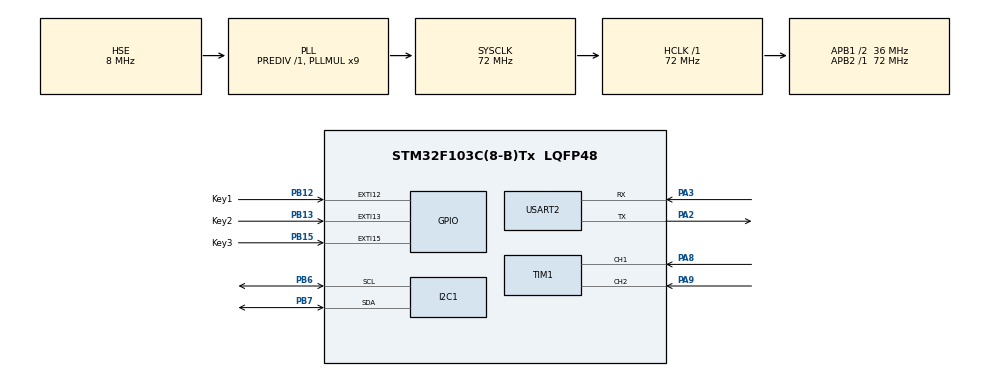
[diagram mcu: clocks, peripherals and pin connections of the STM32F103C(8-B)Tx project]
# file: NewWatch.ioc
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Dma.I2C1_TX.0.Direction=DMA_MEMORY_TO_PERIPH
Dma.I2C1_TX.0.Instance=DMA1_Channel6
Dma.I2C1_TX.0.MemDataAlignment=DMA_MDATAALIGN_BYTE
Dma.I2C1_TX.0.MemInc=DMA_MINC_ENABLE
Dma.I2C1_TX.0.Mode=DMA_NORMAL
Dma.I2C1_TX.0.PeriphDataAlignment=DMA_PDATAALIGN_BYTE
Dma.I2C1_TX.0.PeriphInc=DMA_PINC_DISABLE
Dma.I2C1_TX.0.Priority=DMA_PRIORITY_LOW
Dma.Request0=I2C1_TX
FREERTOS.BinarySemaphores01=KeySem1,Dynamic,NULL,Depleted;oled_dma_sem,Dynamic,NULL,Available
FREERTOS.Queues01=KeyTransmitQueue,16,key_type,0,Dynamic,NULL,NULL;EncoderHandle,16,Knob_message,0,Dynamic,NULL,NULL
FREERTOS.Tasks01=KeyForwardTask,8,128,StartForward,As weak,NULL,Dynamic,NULL,NULL;DisplayTask1,24,256,StartDisplay1,As external,NULL,Dynamic,NULL,NULL;RtcTask,8,128,StartRTC,As external,NULL,Dynamic,NULL,NULL;EncoderTask,40,128,StartEncoder,As external,NULL,Dynamic,NULL,NULL
FREERTOS.configTOTAL_HEAP_SIZE=6042
I2C1.I2C_Mode=I2C_Fast
Mcu.Family=STM32F1
Mcu.Name=STM32F103C(8-B)Tx
Mcu.Package=LQFP48
NVIC.DMA1_Channel6_IRQn=true\:5\:0\:false\:false\:true\:true\:false\:true\:true
NVIC.EXTI15_10_IRQn=true\:7\:0\:true\:false\:true\:false\:true\:true\:true
NVIC.I2C1_EV_IRQn=true\:5\:0\:false\:false\:true\:true\:true\:true\:true
NVIC.PriorityGroup=NVIC_PRIORITYGROUP_4
NVIC.TIM4_IRQn=true\:15\:0\:false\:false\:true\:false\:false\:true\:true
NVIC.TimeBase=TIM4_IRQn
NVIC.TimeBaseIP=TIM4
PA13.Mode=Serial_Wire
PA13.Signal=SYS_JTMS-SWDIO
PA14.Mode=Serial_Wire
PA14.Signal=SYS_JTCK-SWCLK
PA2.Mode=Asynchronous
PA2.Signal=USART2_TX
PA3.Mode=Asynchronous
PA3.Signal=USART2_RX
PA8.Signal=S_TIM1_CH1
PA9.Signal=S_TIM1_CH2
PB12.GPIO_Label=Key1
PB12.GPIO_ModeDefaultEXTI=GPIO_MODE_IT_FALLING
PB12.Signal=GPXTI12
PB13.GPIO_Label=Key2
PB13.GPIO_ModeDefaultEXTI=GPIO_MODE_IT_FALLING
PB13.GPIO_PuPd=GPIO_PULLUP
PB13.Signal=GPXTI13
PB15.GPIO_Label=Key3
PB15.GPIO_ModeDefaultEXTI=GPIO_MODE_IT_FALLING
PB15.GPIO_PuPd=GPIO_PULLUP
PB15.Signal=GPXTI15
PB6.Mode=I2C
PB6.Signal=I2C1_SCL
PB7.Mode=I2C
PB7.Signal=I2C1_SDA
PC14-OSC32_IN.Mode=LSE-External-Oscillator
PC14-OSC32_IN.Signal=RCC_OSC32_IN
PC15-OSC32_OUT.Mode=LSE-External-Oscillator
PC15-OSC32_OUT.Signal=RCC_OSC32_OUT
PD0-OSC_IN.Mode=HSE-External-Oscillator
PD0-OSC_IN.Signal=RCC_OSC_IN
PD1-OSC_OUT.Mode=HSE-External-Oscillator
PD1-OSC_OUT.Signal=RCC_OSC_OUT
ProjectManager.HeapSize=0x200
ProjectManager.StackSize=0x400
ProjectManager.TargetToolchain=CMake
RCC.AHBFreq_Value=72000000
RCC.APB1CLKDivider=RCC_HCLK_DIV2
RCC.APB1Freq_Value=36000000
RCC.APB1TimFreq_Value=72000000
RCC.APB2Freq_Value=72000000
RCC.APB2TimFreq_Value=72000000
RCC.HCLKFreq_Value=72000000
RCC.PLLMUL=RCC_PLL_MUL9
RCC.PLLSourceVirtual=RCC_PLLSOURCE_HSE
RCC.RTCClockSelection=RCC_RTCCLKSOURCE_LSE
RCC.SYSCLKFreq_VALUE=72000000
RCC.SYSCLKSource=RCC_SYSCLKSOURCE_PLLCLK
RCC.USBFreq_Value=72000000
SH.S_TIM1_CH1.0=TIM1_CH1,Encoder_Interface
SH.S_TIM1_CH2.0=TIM1_CH2,Encoder_Interface
TIM1.IC2Polarity=TIM_ICPOLARITY_FALLING
USART2.VirtualMode=VM_ASYNC
VP_FREERTOS_VS_CMSIS_V2.Mode=CMSIS_V2
VP_RTC_VS_RTC_Activate.Mode=RTC_Enabled
VP_SYS_VS_tim4.Mode=TIM4
board=custom

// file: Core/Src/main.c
/* USER CODE BEGIN Header */
/**
  ******************************************************************************
  * @file           : main.c
  * @brief          : Main program body
  ******************************************************************************
  * @attention
  *
  * Copyright (c) 2026 STMicroelectronics.
  * All rights reserved.
  *
  * This software is licensed under terms that can be found in the LICENSE file
  * in the root directory of this software component.
  * If no LICENSE file comes with this software, it is provided AS-IS.
  *
  ******************************************************************************
  */
/* USER CODE END Header */
#include "main.h"
#include "cmsis_os.h"
#include "dma.h"
#include "i2c.h"
#include "rtc.h"
#include "tim.h"
#include "usart.h"
#include "gpio.h"

void SystemClock_Config(void);
void MX_FREERTOS_Init(void);

int main(void)
{

  /* MCU Configuration--------------------------------------------------------*/

  /* Reset of all peripherals, Initializes the Flash interface and the Systick. */
  HAL_Init();

  /* Configure the system clock */
  SystemClock_Config();

  /* Initialize all configured peripherals */
  MX_GPIO_Init();
  MX_DMA_Init();
  MX_I2C1_Init();
  MX_USART2_UART_Init();
  MX_RTC_Init();
  MX_TIM1_Init();

  /* Init scheduler */
  osKernelInitialize();  /* Call init function for freertos objects (in cmsis_os2.c) */
  MX_FREERTOS_Init();

  /* Start scheduler */
  osKernelStart();

  /* We should never get here as control is now taken by the scheduler */

  /* Infinite loop */
  while (1)
  {

  }
}

void SystemClock_Config(void)
{
  RCC_OscInitTypeDef RCC_OscInitStruct = {0};
  RCC_ClkInitTypeDef RCC_ClkInitStruct = {0};
  RCC_PeriphCLKInitTypeDef PeriphClkInit = {0};

  /** Initializes the RCC Oscillators according to the specified parameters
  * in the RCC_OscInitTypeDef structure.
  */
  RCC_OscInitStruct.OscillatorType = RCC_OSCILLATORTYPE_HSE|RCC_OSCILLATORTYPE_LSE;
  RCC_OscInitStruct.HSEState = RCC_HSE_ON;
  RCC_OscInitStruct.HSEPredivValue = RCC_HSE_PREDIV_DIV1;
  RCC_OscInitStruct.LSEState = RCC_LSE_ON;
  RCC_OscInitStruct.HSIState = RCC_HSI_ON;
  RCC_OscInitStruct.PLL.PLLState = RCC_PLL_ON;
  RCC_OscInitStruct.PLL.PLLSource = RCC_PLLSOURCE_HSE;
  RCC_OscInitStruct.PLL.PLLMUL = RCC_PLL_MUL9;
  if (HAL_RCC_OscConfig(&RCC_OscInitStruct) != HAL_OK)
  {
    Error_Handler();
  }

  /** Initializes the CPU, AHB and APB buses clocks
  */
  RCC_ClkInitStruct.ClockType = RCC_CLOCKTYPE_HCLK|RCC_CLOCKTYPE_SYSCLK
                              |RCC_CLOCKTYPE_PCLK1|RCC_CLOCKTYPE_PCLK2;
  RCC_ClkInitStruct.SYSCLKSource = RCC_SYSCLKSOURCE_PLLCLK;
  RCC_ClkInitStruct.AHBCLKDivider = RCC_SYSCLK_DIV1;
  RCC_ClkInitStruct.APB1CLKDivider = RCC_HCLK_DIV2;
  RCC_ClkInitStruct.APB2CLKDivider = RCC_HCLK_DIV1;

  if (HAL_RCC_ClockConfig(&RCC_ClkInitStruct, FLASH_LATENCY_2) != HAL_OK)
  {
    Error_Handler();
  }
  PeriphClkInit.PeriphClockSelection = RCC_PERIPHCLK_RTC;
  PeriphClkInit.RTCClockSelection = RCC_RTCCLKSOURCE_LSE;
  if (HAL_RCCEx_PeriphCLKConfig(&PeriphClkInit) != HAL_OK)
  {
    Error_Handler();
  }
}

void HAL_TIM_PeriodElapsedCallback(TIM_HandleTypeDef *htim)
{
  if (htim->Instance == TIM4)
  {
    HAL_IncTick();
  }
}

void Error_Handler(void)
{
  __disable_irq();
  while (1)
  {
  }
}

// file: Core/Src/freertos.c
/* USER CODE BEGIN Header */
/**
  ******************************************************************************
  * File Name          : freertos.c
  * Description        : Code for freertos applications
  ******************************************************************************
  * @attention
  *
  * Copyright (c) 2026 STMicroelectronics.
  * All rights reserved.
  *
  * This software is licensed under terms that can be found in the LICENSE file
  * in the root directory of this software component.
  * If no LICENSE file comes with this software, it is provided AS-IS.
  *
  ******************************************************************************
  */
/* USER CODE END Header */

#include "FreeRTOS.h"
#include "task.h"
#include "main.h"
#include "cmsis_os.h"

/* USER CODE BEGIN Includes */
#include "keycontrol.h"
#include "knob.h"
#include <string.h>
/* USER CODE END Includes */

/* Definitions for KeyForwardTask */
osThreadId_t KeyForwardTaskHandle;
const osThreadAttr_t KeyForwardTask_attributes = {
  .name = "KeyForwardTask",
  .stack_size = 128 * 4,
  .priority = (osPriority_t) osPriorityLow,
};
/* Definitions for DisplayTask1 */
osThreadId_t DisplayTask1Handle;
const osThreadAttr_t DisplayTask1_attributes = {
  .name = "DisplayTask1",
  .stack_size = 256 * 4,
  .priority = (osPriority_t) osPriorityNormal,
};
/* Definitions for RtcTask */
osThreadId_t RtcTaskHandle;
const osThreadAttr_t RtcTask_attributes = {
  .name = "RtcTask",
  .stack_size = 128 * 4,
  .priority = (osPriority_t) osPriorityLow,
};
/* Definitions for EncoderTask */
osThreadId_t EncoderTaskHandle;
const osThreadAttr_t EncoderTask_attributes = {
  .name = "EncoderTask",
  .stack_size = 128 * 4,
  .priority = (osPriority_t) osPriorityHigh,
};
/* Definitions for KeyTransmitQueue */
osMessageQueueId_t KeyTransmitQueueHandle;
const osMessageQueueAttr_t KeyTransmitQueue_attributes = {
  .name = "KeyTransmitQueue"
};
/* Definitions for EncoderHandle */
osMessageQueueId_t EncoderHandleHandle;
const osMessageQueueAttr_t EncoderHandle_attributes = {
  .name = "EncoderHandle"
};
/* Definitions for KeySem1 */
osSemaphoreId_t KeySem1Handle;
const osSemaphoreAttr_t KeySem1_attributes = {
  .name = "KeySem1"
};
/* Definitions for oled_dma_sem */
osSemaphoreId_t oled_dma_semHandle;
const osSemaphoreAttr_t oled_dma_sem_attributes = {
  .name = "oled_dma_sem"
};

void StartForward(void *argument);
extern void StartDisplay1(void *argument);
extern void StartRTC(void *argument);
extern void StartEncoder(void *argument);

void MX_FREERTOS_Init(void); /* (MISRA C 2004 rule 8.1) */

void MX_FREERTOS_Init(void) {

  /* Create the semaphores(s) */
  /* creation of KeySem1 */
  KeySem1Handle = osSemaphoreNew(1, 0, &KeySem1_attributes);

  /* creation of oled_dma_sem */
  oled_dma_semHandle = osSemaphoreNew(1, 1, &oled_dma_sem_attributes);

  /* Create the queue(s) */
  /* creation of KeyTransmitQueue */
  KeyTransmitQueueHandle = osMessageQueueNew (16, sizeof(key_type), &KeyTransmitQueue_attributes);

  /* creation of EncoderHandle */
  EncoderHandleHandle = osMessageQueueNew (16, sizeof(Knob_message), &EncoderHandle_attributes);

  /* Create the thread(s) */
  /* creation of KeyForwardTask */
  KeyForwardTaskHandle = osThreadNew(StartForward, NULL, &KeyForwardTask_attributes);

  /* creation of DisplayTask1 */
  DisplayTask1Handle = osThreadNew(StartDisplay1, NULL, &DisplayTask1_attributes);

  /* creation of RtcTask */
  RtcTaskHandle = osThreadNew(StartRTC, NULL, &RtcTask_attributes);

  /* creation of EncoderTask */
  EncoderTaskHandle = osThreadNew(StartEncoder, NULL, &EncoderTask_attributes);

}

__weak void StartForward(void *argument)
{
  /* USER CODE BEGIN StartForward */
  /* Infinite loop */
  for(;;)
  {
    osDelay(1000);
  }
  /* USER CODE END StartForward */
}
